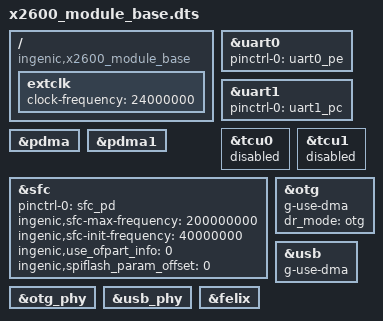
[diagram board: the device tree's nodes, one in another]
/dts-v1/;

#include <dt-bindings/input/input.h>
#include "x2600.dtsi"
#include <dt-bindings/interrupt-controller/irq.h>
#include <generated/autoconf.h>

/ {
	compatible = "ingenic,x2600_module_base", "ingenic,x2600";
};

&uart0 {
	status = "okay";
	pinctrl-names = "default";
	pinctrl-0 = <&uart0_pe>;
};

&uart1 {
	status = "okay";
	pinctrl-names = "default";
	pinctrl-0 = <&uart1_pc>;
};


&tcu0 {
	status = "disable";
};

&tcu1 {
	status = "disable";
};

&pdma {
	status = "okay";
};

&pdma1 {
	status = "okay";
};

&sfc {
	status = "okay";
	pinctrl-names = "default";
	pinctrl-0 = <&sfc_pd>;
	ingenic,sfc-max-frequency = <200000000>;
	ingenic,sfc-init-frequency= <40000000>;
	ingenic,use_ofpart_info  = /bits/ 8 <0>;
	ingenic,spiflash_param_offset = <0>;


};

&otg {
	g-use-dma;
	dr_mode = "otg"; // host,peripheral,otg
	status = "okay";
};

&usb {
	g-use-dma;
	status = "okay";
};

&otg_phy {
	status = "okay";
};

&usb_phy {
	status = "okay";
};

&felix {
	status = "okay";
};

/ {

	extclk: extclk {
		clock-frequency = <24000000>;
	};

	};
